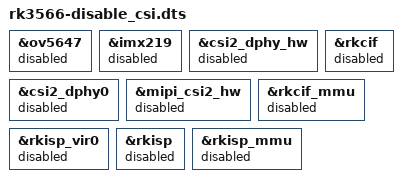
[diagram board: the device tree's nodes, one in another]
/dts-v1/;
/plugin/;

/ {
	// Disable ov5647 sensor
	fragment@0 {
		target = <&ov5647>;
		__overlay__ {
			status = "disabled";
		};
	};

	// Disable imx219 sensor
	fragment@1 {
		target = <&imx219>;
		__overlay__ {
			status = "disabled";
		};
	};

	// Disable CSI
	fragment@2 {
		target = <&csi2_dphy_hw>;
		__overlay__ {
			status = "disabled";
		};
	};

	fragment@3 {
		target = <&csi2_dphy0>;
		__overlay__ {
			status = "disabled";
		};
	};

	fragment@4 {
		target = <&mipi_csi2_hw>;
		__overlay__ {
			status = "disabled";
		};
	};

	// Disable cif & isp
	fragment@5 {
		target = <&rkcif>;
		__overlay__ {
			status = "disabled";
		};
	};

	fragment@6 {
		target = <&rkcif_mmu>;
		__overlay__ {
			status = "disabled";
		};
	};

	fragment@7 {
		target = <&rkisp_vir0>;
		__overlay__ {
			status = "disabled";
		};
	};

	fragment@8 {
		target = <&rkisp>;
		__overlay__ {
			status = "disabled";
		};
	};

	fragment@9 {
		target = <&rkisp_mmu>;
		__overlay__ {
			status = "disabled";
		};
	};
};
